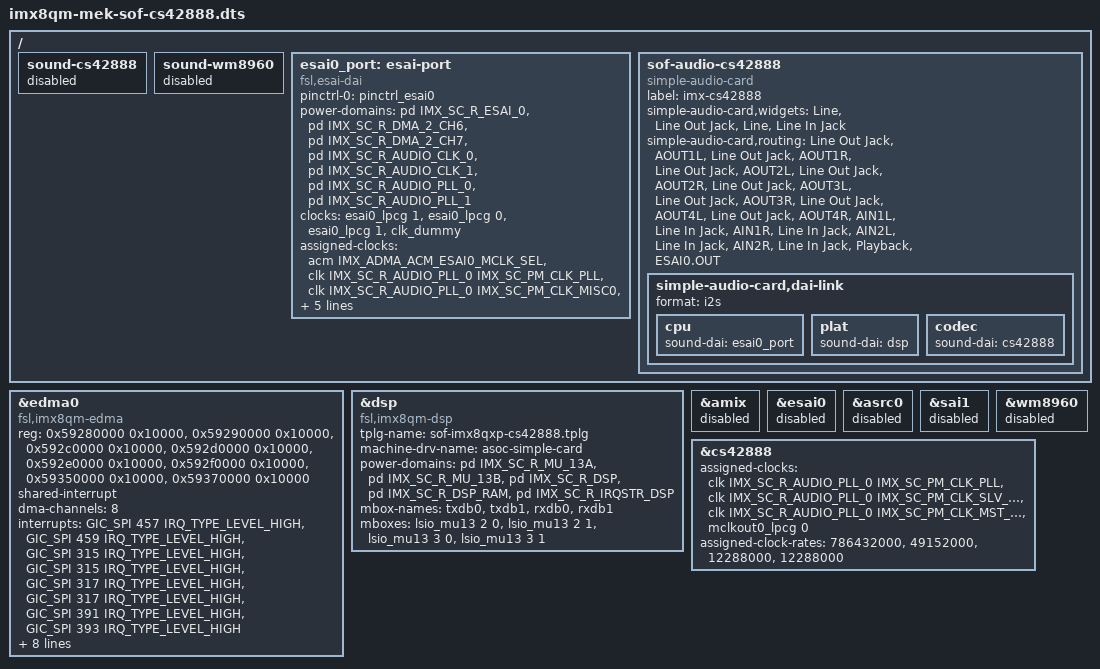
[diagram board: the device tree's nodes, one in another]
// SPDX-License-Identifier: GPL-2.0+
// Copyright NXP 2020

#include "imx8qm-mek-rpmsg.dts"

/ {
	sound-cs42888 {
		status = "disabled";
	};

	sound-wm8960 {
		status = "disabled";
	};

	esai0_port: esai-port {
		#sound-dai-cells = <0>;
		compatible = "fsl,esai-dai";

		pinctrl-names = "default";
		pinctrl-0 = <&pinctrl_esai0>;

		power-domains = <&pd IMX_SC_R_ESAI_0>,
			<&pd IMX_SC_R_DMA_2_CH6>,
			<&pd IMX_SC_R_DMA_2_CH7>,
			<&pd IMX_SC_R_AUDIO_CLK_0>,
			<&pd IMX_SC_R_AUDIO_CLK_1>,
			<&pd IMX_SC_R_AUDIO_PLL_0>,
			<&pd IMX_SC_R_AUDIO_PLL_1>;

		clocks = <&esai0_lpcg 1>, <&esai0_lpcg 0>,  <&esai0_lpcg 1>,
			<&clk_dummy>;
		clock-names = "core", "extal", "fsys", "spba";
		assigned-clocks = <&acm IMX_ADMA_ACM_ESAI0_MCLK_SEL>,
			<&clk IMX_SC_R_AUDIO_PLL_0 IMX_SC_PM_CLK_PLL>,
			<&clk IMX_SC_R_AUDIO_PLL_0 IMX_SC_PM_CLK_MISC0>,
			<&clk IMX_SC_R_AUDIO_PLL_0 IMX_SC_PM_CLK_MISC1>,
			<&esai0_lpcg 0>;
		assigned-clock-parents = <&aud_pll_div0_lpcg 0>;
		assigned-clock-rates = <0>, <786432000>, <49152000>, <12288000>, <49152000>;
		status="okay";
	};

	sof-audio-cs42888 {
		compatible = "simple-audio-card";
		label = "imx-cs42888";
		simple-audio-card,widgets =
			"Line", "Line Out Jack",
			"Line", "Line In Jack";
		simple-audio-card,routing =
			"Line Out Jack", "AOUT1L",
			"Line Out Jack", "AOUT1R",
			"Line Out Jack", "AOUT2L",
			"Line Out Jack", "AOUT2R",
			"Line Out Jack", "AOUT3L",
			"Line Out Jack", "AOUT3R",
			"Line Out Jack", "AOUT4L",
			"Line Out Jack", "AOUT4R",
			"AIN1L", "Line In Jack",
			"AIN1R", "Line In Jack",
			"AIN2L", "Line In Jack",
			"AIN2R", "Line In Jack",
			"Playback",  "ESAI0.OUT";
		status = "okay";
		simple-audio-card,dai-link {
			format = "i2s";
			cpu {
				sound-dai = <&esai0_port>;
			};
			plat {
				sound-dai = <&dsp>;
			};
			codec {
				sound-dai = <&cs42888>;
			};
		};
	};
};

&edma0 {
	compatible = "fsl,imx8qm-edma";
	reg = <0x59280000 0x10000>, /* spdif0 rx */
		<0x59290000 0x10000>, /* spdif0 tx */
		<0x592c0000 0x10000>, /* sai0 rx */
		<0x592d0000 0x10000>, /* sai0 tx */
		<0x592e0000 0x10000>, /* sai1 rx */
		<0x592f0000 0x10000>, /* sai1 tx */
		<0x59350000 0x10000>,
		<0x59370000 0x10000>;
	#dma-cells = <3>;
	shared-interrupt;
	dma-channels = <8>;
	interrupts = <GIC_SPI 457 IRQ_TYPE_LEVEL_HIGH>, /* spdif0 */
			<GIC_SPI 459 IRQ_TYPE_LEVEL_HIGH>,
			<GIC_SPI 315 IRQ_TYPE_LEVEL_HIGH>, /* sai0 */
			<GIC_SPI 315 IRQ_TYPE_LEVEL_HIGH>,
			<GIC_SPI 317 IRQ_TYPE_LEVEL_HIGH>, /* sai1 */
			<GIC_SPI 317 IRQ_TYPE_LEVEL_HIGH>,
			<GIC_SPI 391 IRQ_TYPE_LEVEL_HIGH>,
			<GIC_SPI 393 IRQ_TYPE_LEVEL_HIGH>;
	interrupt-names = "edma2-chan8-rx", "edma2-chan9-tx", /* spdif0 */
			"edma2-chan12-rx", "edma2-chan13-tx", /* sai0 */
			"edma2-chan14-rx", "edma2-chan15-tx", /* sai1 */
			"edma2-chan21-tx",		/* gpt5 */
			"edma2-chan23-rx";		/* gpt7 */
	power-domains = <&pd IMX_SC_R_DMA_2_CH8>,
			<&pd IMX_SC_R_DMA_2_CH9>,
			<&pd IMX_SC_R_DMA_2_CH12>,
			<&pd IMX_SC_R_DMA_2_CH13>,
			<&pd IMX_SC_R_DMA_2_CH14>,
			<&pd IMX_SC_R_DMA_2_CH15>,
			<&pd IMX_SC_R_DMA_2_CH21>,
			<&pd IMX_SC_R_DMA_2_CH23>;
	power-domain-names = "edma2-chan8", "edma2-chan9",
			"edma2-chan12", "edma2-chan13",
			"edma2-chan14", "edma2-chan15",
			"edma2-chan21", "edma2-chan23";
	status = "okay";
};

&dsp {
	compatible = "fsl,imx8qm-dsp";
	#sound-dai-cells = <0>;
	tplg-name = "sof-imx8qxp-cs42888.tplg";
	machine-drv-name = "asoc-simple-card";
	status = "okay";
	power-domains = <&pd IMX_SC_R_MU_13A>,
			<&pd IMX_SC_R_MU_13B>,
			<&pd IMX_SC_R_DSP>,
			<&pd IMX_SC_R_DSP_RAM>,
			<&pd IMX_SC_R_IRQSTR_DSP>;
	mbox-names = "txdb0", "txdb1", "rxdb0", "rxdb1";
	mboxes = <&lsio_mu13 2 0>,
		<&lsio_mu13 2 1>,
		<&lsio_mu13 3 0>,
		<&lsio_mu13 3 1>;
};

&amix {
	status = "disabled";
};

&esai0 {
	status = "disabled";
};

&asrc0 {
	status = "disabled";
};

&sai1 {
	status = "disabled";
};

&wm8960 {
	status = "disabled";
};

&cs42888 {
	#sound-dai-cells = <0>;
	assigned-clocks = <&clk IMX_SC_R_AUDIO_PLL_0 IMX_SC_PM_CLK_PLL>,
			  <&clk IMX_SC_R_AUDIO_PLL_0 IMX_SC_PM_CLK_SLV_BUS>,
			  <&clk IMX_SC_R_AUDIO_PLL_0 IMX_SC_PM_CLK_MST_BUS>,
			  <&mclkout0_lpcg 0>;
	assigned-clock-rates = <786432000>, <49152000>, <12288000>, <12288000>;
	status = "okay";
};
